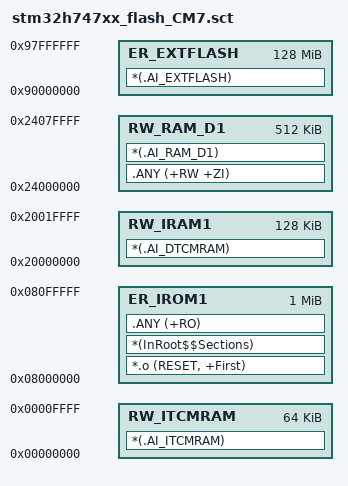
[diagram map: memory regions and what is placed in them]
LR_IROM1 0x08000000 0x00100000	{
	ER_IROM1 0x08000000 0x100000 {
		*.o (RESET, +First)
		*(InRoot$$Sections)
		.ANY (+RO)
	}
	RW_IRAM1 0x20000000 0x20000 {
		*(.AI_DTCMRAM)
	}
	RW_ITCMRAM 0x0 0x10000 {
		*(.AI_ITCMRAM)
	}
	RW_RAM_D1 0x24000000 0x80000 {
		.ANY (+RW +ZI)
		*(.AI_RAM_D1)
	}
}
LR_EXTFLASH 0x90000000 0x8000000	{
	ER_EXTFLASH 0x90000000 0x8000000 {
		*(.AI_EXTFLASH)
	}
}
